# WLR089U0 register map
Vendor: Microchip
Registers are 32-bit, read-write, reset 0x0 unless marked. A register's access mark holds for its fields unless they carry their own. Addresses are absolute, and some are shared; only a register's first bit layout is shown; [hi:lo] are bit positions; {n}, {i} and the like mark numbered series; 'fields as' and 'values as' point back to an identical list.

## RSTC
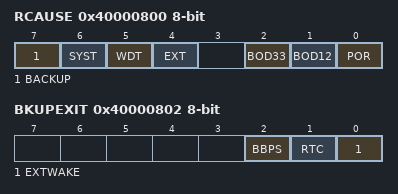
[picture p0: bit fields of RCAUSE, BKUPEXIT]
0x40000800 RCAUSE 8-bit ro reset not defined
  [7] BACKUP — Backup Reset
  [6] SYST — System Reset Request
  [5] WDT — Watchdog Reset
  [4] EXT — External Reset
  [2] BOD33 — Brown Out 33 Detector Reset
  [1] BOD12 — Brown Out 12 Detector Reset
  [0] POR — Power On Reset
0x40000802 BKUPEXIT 8-bit ro reset not defined
  [2] BBPS — Battery Backup Power Switch
  [1] RTC — Real Timer Counter Interrupt
  [0] EXTWAKE — External Wakeup
0x40000804 WKDBCONF 8-bit
  [4:0] WKDBCNT — Wakeup Debounce Counter
    0=OFF (No debouncing.Input pin is low or high level sensitive depending on its WKPOLx bit.); 1=2CK32 (Input pin shall be active for at least two 32kHz clock period.); 2=3CK32 (Input pin shall be active for at least three 32kHz clock period.); 3=32CK32 (Input pin shall be active for at least 32 32kHz clock period.); 4=512CK32 (Input pin shall be active for at least 512 32kHz clock period.); 5=4096CK32 (Input pin shall be active for at least 4096 32kHz clock period.); 6=32768CK32 (Input pin shall be active for at least 32768 32kHz clock period.)
0x40000808 WKPOL 16-bit
  [7:0] WKPOL — Wakeup Polarity
0x4000080C WKEN 16-bit
  [7:0] WKEN — Wakeup Enable
0x40000810 WKCAUSE 16-bit
  [15:0] WKCAUSE — Wakeup Cause

## OSC32KCTRL
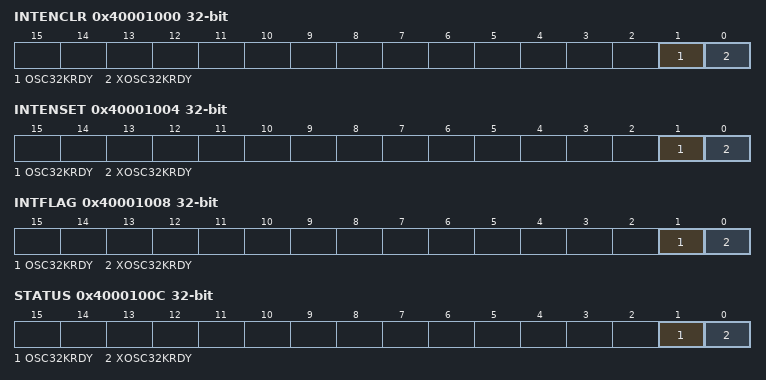
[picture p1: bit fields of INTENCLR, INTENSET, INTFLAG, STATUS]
0x40001000 INTENCLR
  [1] OSC32KRDY — OSC32K Ready Interrupt Enable
  [0] XOSC32KRDY — XOSC32K Ready Interrupt Enable
0x40001004 INTENSET
  fields as INTENCLR
0x40001008 INTFLAG
  [1] OSC32KRDY — OSC32K Ready
  [0] XOSC32KRDY — XOSC32K Ready
0x4000100C STATUS ro
  [1] OSC32KRDY — OSC32K Ready
  [0] XOSC32KRDY — XOSC32K Ready
0x40001010 RTCCTRL
  [2:0] RTCSEL — RTC Clock Selection
    0=ULP1K (1.024kHz from 32kHz internal ULP oscillator); 1=ULP32K (32.768kHz from 32kHz internal ULP oscillator); 2=OSC1K (1.024kHz from 32.768kHz internal oscillator); 3=OSC32K (32.768kHz from 32.768kHz internal oscillator); 4=XOSC1K (1.024kHz from 32.768kHz internal oscillator); 5=XOSC32K (32.768kHz from 32.768kHz external crystal oscillator)
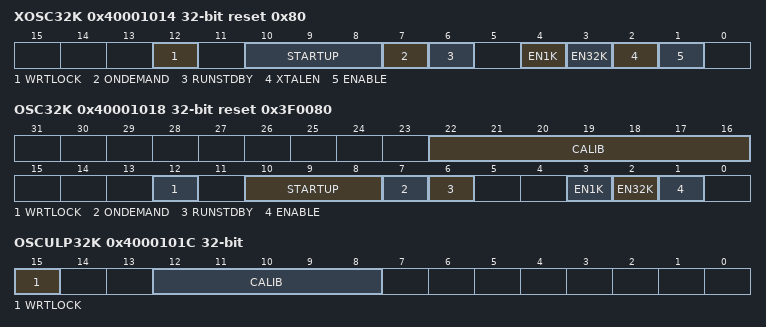
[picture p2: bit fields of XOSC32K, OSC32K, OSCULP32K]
0x40001014 XOSC32K reset 0x80
  [12] WRTLOCK — Write Lock
  [10:8] STARTUP — Oscillator Start-Up Time
    0=CYCLE2048 (62.5 ms); 1=CYCLE4096 (125 ms); 2=CYCLE16384 (500 ms); 3=CYCLE32768 (1000 ms); 4=CYCLE65536 (2000 ms); 5=CYCLE131072 (4000 ms); 6=CYCLE262144 (8000 ms)
  [7] ONDEMAND — On Demand Control
  [6] RUNSTDBY — Run in Standby
  [4] EN1K — 1kHz Output Enable
  [3] EN32K — 32kHz Output Enable
  [2] XTALEN — Crystal Oscillator Enable
  [1] ENABLE — Oscillator Enable
0x40001018 OSC32K reset 0x3F0080
  [22:16] CALIB — Oscillator Calibration
  [12] WRTLOCK — Write Lock
  [10:8] STARTUP — Oscillator Start-Up Time
    0=CYCLE3 (0.092 ms); 1=CYCLE4 (0.122 ms); 2=CYCLE6 (0.183 ms); 3=CYCLE10 (0.305 ms); 4=CYCLE18 (0.549 ms); 5=CYCLE34 (1.038 ms); 6=CYCLE66 (2.014 ms); 7=CYCLE130 (3.967 ms)
  [7] ONDEMAND — On Demand Control
  [6] RUNSTDBY — Run in Standby
  [3] EN1K — 1kHz Output Enable
  [2] EN32K — 32kHz Output Enable
  [1] ENABLE — Oscillator Enable
0x4000101C OSCULP32K reset not defined
  [15] WRTLOCK — Write Lock
  [12:8] CALIB — Oscillator Calibration

## GCLK
0x40001800 CTRLA 8-bit
  [0] SWRST — Software Reset
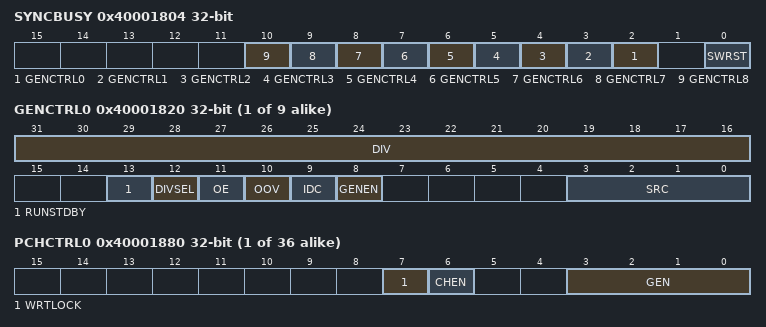
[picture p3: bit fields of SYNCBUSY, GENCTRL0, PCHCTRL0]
0x40001804 SYNCBUSY ro
  [n+2] GENCTRL{n} (n=0..8) — Generic Clock Generator Control {n} Synchronization Busy bits
    1=GCLK0 (Generic clock generator 0); 2=GCLK1 (Generic clock generator 1); 4=GCLK2 (Generic clock generator 2); 8=GCLK3 (Generic clock generator 3); 16=GCLK4 (Generic clock generator 4); 32=GCLK5 (Generic clock generator 5); 64=GCLK6 (Generic clock generator 6); 128=GCLK7 (Generic clock generator 7); 0x100=GCLK8 (Generic clock generator 8)
  [0] SWRST — Software Reset Synchroniation Busy bit
{0x40001820+4i} GENCTRL{i} (i=0..8)
  [31:16] DIV — Division Factor
  [13] RUNSTDBY — Run in Standby
  [12] DIVSEL — Divide Selection
    0=DIV1 (Divide input directly by divider factor); 1=DIV2 (Divide input by 2^(divider factor+ 1))
  [11] OE — Output Enable
  [10] OOV — Output Off Value
  [9] IDC — Improve Duty Cycle
  [8] GENEN — Generic Clock Generator Enable
  [3:0] SRC — Source Select
    0=XOSC (XOSC oscillator output); 1=GCLKIN (Generator input pad); 2=GCLKGEN1 (Generic clock generator 1 output); 3=OSCULP32K (OSCULP32K oscillator output); 4=OSC32K (OSC32K oscillator output); 5=XOSC32K (XOSC32K oscillator output); 6=OSC16M (OSC16M oscillator output); 7=DFLL48M (DFLL48M output); 8=DPLL96M (DPLL96M output)
{0x40001880+4i} PCHCTRL{i} (i=0..35)
  [7] WRTLOCK — Write Lock
  [6] CHEN — Channel Enable
  [3:0] GEN — Generic Clock Generator
    {v}=GCLK{v} (Generic clock generator {v}) (v=0..8)
